# FM33LC0XX register map
File version: 1.0
CPU: Cortex-M0 r1p0, little endian, no MPU, no FPU, 3 interrupt priority bits
Registers are 32-bit, read-write, reset 0x0 unless marked. A register's access mark holds for its fields unless they carry their own. Offsets are from the block's base; [hi:lo] are bit positions; {n}, {i} and the like mark numbered series.

## ADC — ADC module information
Base 0x4001AC00
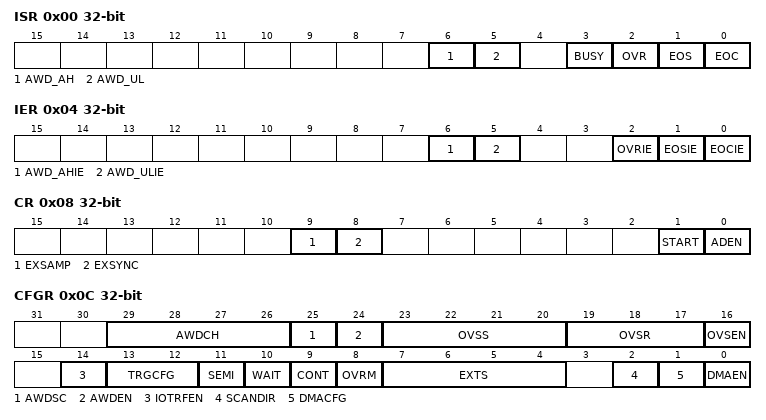
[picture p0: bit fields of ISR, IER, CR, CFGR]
0x00 ISR access per field — ADC Interrupt and Status Register
  [6] AWD_AH rw — AWD_AH field description
  [5] AWD_UL rw — AWD_UL field description
  [3] BUSY ro — BUSY field description
  [2] OVR rw — OVR field description
  [1] EOS rw — EOS field description
  [0] EOC rw — EOC field description
0x04 IER — ADC Interrupt Enable Register
  [6] AWD_AHIE — AWD_AHIE field description
  [5] AWD_ULIE — AWD_ULIE field description
  [2] OVRIE — OVRIE field description
  [1] EOSIE — EOSIE field description
  [0] EOCIE — EOCIE field description
0x08 CR — ADC Control Register
  [9] EXSAMP — EXSAMP field description
  [8] EXSYNC — EXSYNC field description
  [1] START — START field description
  [0] ADEN — ADEN field description
0x0C CFGR — ADC Config Register
  [29:26] AWDCH — AWDCH field description
  [25] AWDSC — AWDSC field description
  [24] AWDEN — AWDEN field description
  [23:20] OVSS — OVSS field description
  [19:17] OVSR — OVSR field description
  [16] OVSEN — OVSEN field description
  [14] IOTRFEN — IOTRFEN field description
  [13:12] TRGCFG — TRGCFG field description
  [11] SEMI — SEMI field description
  [10] WAIT — WAIT field description
  [9] CONT — CONT field description
  [8] OVRM — OVRM field description
  [7:4] EXTS — EXTS field description
  [2] SCANDIR — SCANDIR field description
  [1] DMACFG — DMACFG field description
  [0] DMAEN — DMAEN field description
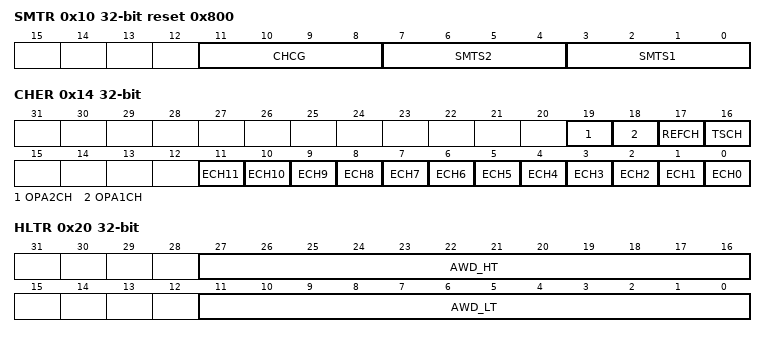
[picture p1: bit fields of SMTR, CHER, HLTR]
0x10 SMTR reset 0x800 — ADC Sampling Time Register
  [11:8] CHCG — CHCG field description
  [7:4] SMTS2 — SMTS2 field description
  [3:0] SMTS1 — SMTS1 field description
0x14 CHER — ADC Channel Enable Register
  [19] OPA2CH — OPA2CH field description
  [18] OPA1CH — OPA1CH field description
  [17] REFCH — REFCH field description
  [16] TSCH — TSCH field description
  [n] ECH{n} (n=0..11) — ECH{n} field description
0x18 DR ro — ADC Data Register
  [15:0] DATA — DATA field description
0x1C SAMPT — ADC Sampling Register
  [0] SAMPT_S — SAMPT_S field description
0x20 HLTR — ADC analog watchdog Threshold Register
  [27:16] AWD_HT — AWD_HT field description
  [11:0] AWD_LT — AWD_LT field description

## GPIOA — GPIOA module information
Base 0x40000C00
Same registers: GPIOB 0x40000C40, GPIOC 0x40000C80, GPIOD 0x40000CC0
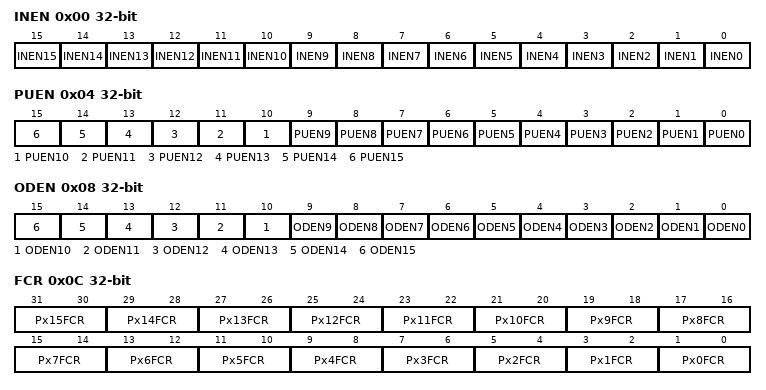
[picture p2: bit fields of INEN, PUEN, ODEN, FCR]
0x00 INEN — GPIOA Input Enable Register
  [n] INEN{n} (n=0..15) — INEN{n} field description
0x04 PUEN — GPIOA Pull-Up Enable Register
  [n] PUEN{n} (n=0..15) — PUEN{n} field description
0x08 ODEN — GPIOA Open-Drain Enable Register
  [n] ODEN{n} (n=0..15) — ODEN{n} field description
0x0C FCR — GPIOA Function Control Register
  [2n+1:2n] Px{n}FCR (n=0..15) — Px{n}FCR field description
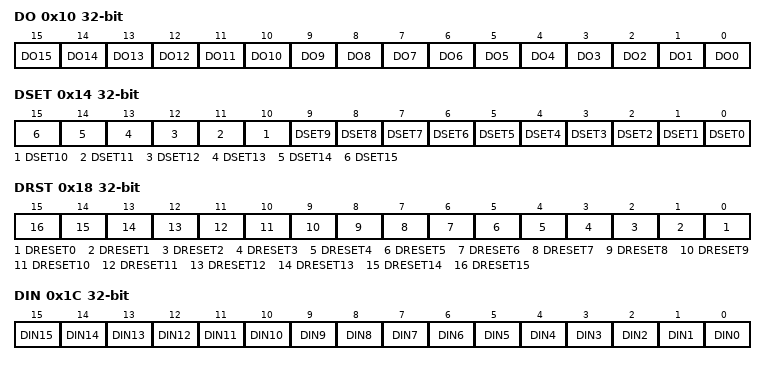
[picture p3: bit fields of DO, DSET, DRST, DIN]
0x10 DO — GPIOA Data Output Register
  [n] DO{n} (n=0..15) — DO{n} field description
0x14 DSET wo — GPIOA Data Set Register
  [n] DSET{n} (n=0..15) — DSET{n} field description
0x18 DRST wo — GPIOA Data Reset Register
  [n] DRESET{n} (n=0..15) — DRESET{n} field description
0x1C DIN ro — GPIOA Data Input Register
  [n] DIN{n} (n=0..15) — DIN{n} field description
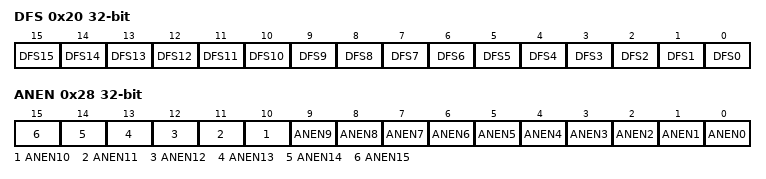
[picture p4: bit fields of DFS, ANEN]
0x20 DFS — GPIOA Digital Function Select
  [n] DFS{n} (n=0..15) — DFS{n} field description
0x28 ANEN — GPIOAAnalog channel Enable Register
  [n] ANEN{n} (n=0..15) — ANEN{n} field description

## GPIO — GPIO module information
Base 0x40000D00
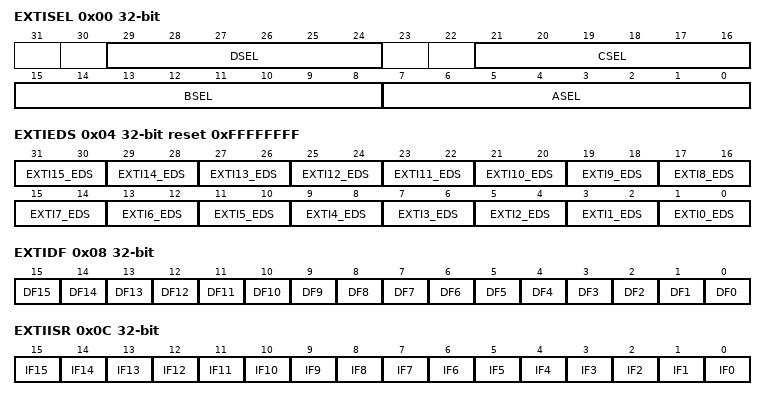
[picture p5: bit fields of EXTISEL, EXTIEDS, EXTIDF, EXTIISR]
0x00 EXTISEL — External Interrupt input Select Register
  [29:24] DSEL — DSEL field description
  [21:16] CSEL — CSEL field description
  [15:8] BSEL — BSEL field description
  [7:0] ASEL — ASEL field description
0x04 EXTIEDS reset 0xFFFFFFFF — External Interrupt Edge Select and Enable Register
  [2n+1:2n] EXTI{n}_EDS (n=0..15) — EXTI{n}_EDS field description
0x08 EXTIDF — External Interrupt Digital Filter Register
  [n] DF{n} (n=0..15) — DF{n} field description
0x0C EXTIISR — External Interrupt and Status Register
  [n] IF{n} (n=0..15) — IF{n} field description
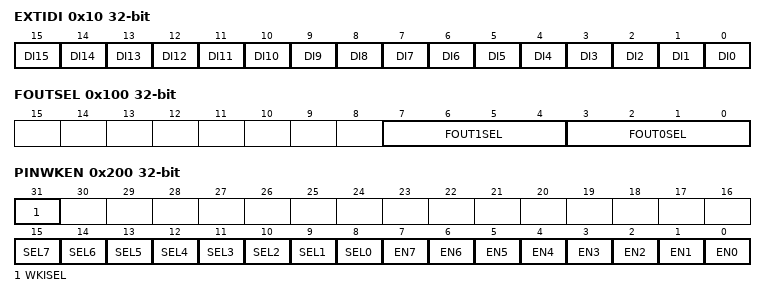
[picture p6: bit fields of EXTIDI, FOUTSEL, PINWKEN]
0x10 EXTIDI ro — External Interrupt Data Input Register
  [n] DI{n} (n=0..15) — DI{n} field description
0x100 FOUTSEL — Frequency Output Select Register
  [7:4] FOUT1SEL — FOUT1SEL field description
  [3:0] FOUT0SEL — FOUT0SEL field description
0x200 PINWKEN — Wakeup Enable Register
  [31] WKISEL — WKISEL field description
  [n+8] SEL{n} (n=0..7) — SEL{n} field description
  [n] EN{n} (n=0..7) — EN{n} field description

## SCU — SCU module information
Base 0x40000000
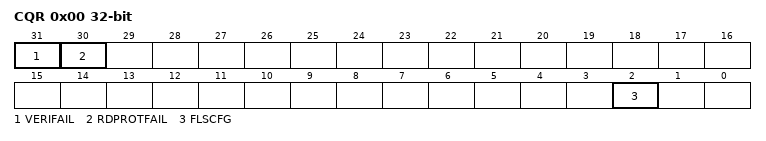
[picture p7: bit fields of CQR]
0x00 CQR — Memory Capacity Query Register
  [31] VERIFAIL — VERIFAIL field description
  [30] RDPROTFAIL — RDPROTFAIL field description
  [2] FLSCFG — FLSCFG field description
